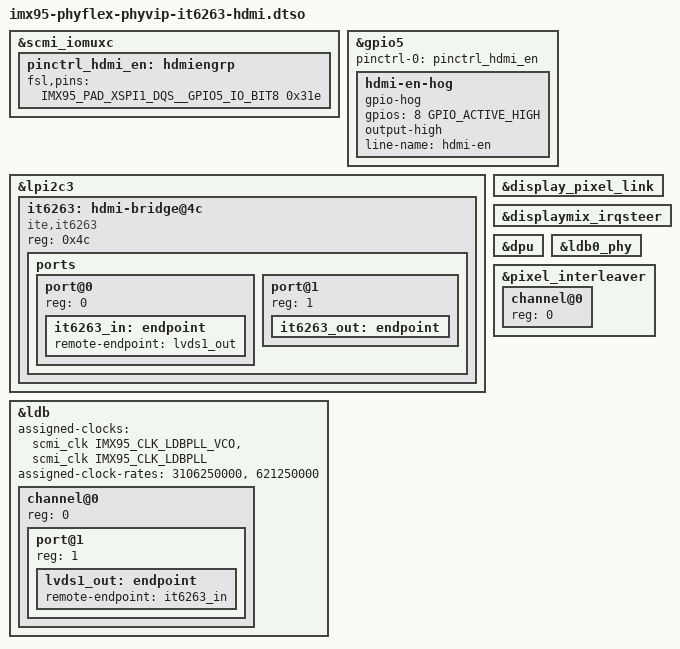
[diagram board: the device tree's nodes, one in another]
// SPDX-License-Identifier: GPL-2.0-only
/*
 * Device Tree Overlay: ITE IT6263 LVDS-to-HDMI bridge
 * Target board: imx95-phyflex-phyvip-1
 *
 * Aktivierung in /boot/overlays.txt:
 *   fit_overlay_conf=conf-imx95-phyflex-phyvip-it6263-hdmi.dtbo
 *
 * LDB-KANAL: channel@0, NICHT channel@1.
 *
 * Diese Datei stammt aus todo/meta-hdmi und war dort fuer das
 * phyBOARD-Libra RDK geschrieben, wo die Bruecke an LVDS2 = LDB channel@1
 * haengt. Auf dem phyVIP-Carrier ist die Belegung anders; die urspruenglich
 * uebernommene channel@1-Fassung hat deshalb einen Kanal bespielt, der hier
 * gar nicht angeschlossen ist. Aus dem Carrier-Schaltplan
 * PV-05832-001-1645-0-004:
 *
 *   Blatt 11 "FPSC_Unused"  -> FPSC LVDS2 (Netze X_LVDS1_*) endet in
 *                              No-Connects. LDB channel@1 ist tot.
 *   Blatt 9  "FPSC_Connector" -> FPSC LVDS1 (Netze X_LVDS0_*) fuehrt nach
 *                              13-C4/13-D4, also auf CON2.
 *   Blatt 13 "Erweiterungsboard-Steckverbinder" -> X_LVDS0_* liegt auf CON2
 *                              (X13X13). Dort sitzt die Bruecke.
 *
 * Messbar am Symptom: mit channel@1 blieb disp1pix auf 24 MHz mit
 * Enable-Count 0, obwohl der Modeset fehlerfrei durchlief, und der IT6263
 * meldete "failed to wait for video stable".
 *
 * PIXELTAKT: eingestellt auf 88,75 MHz = 1440x900@60.
 * Der NXP-Fork des Treibers (drivers/gpu/drm/bridge/it6263.c, bindet trotz
 * compatible "ite,it6263") fuehrt in it6263_bad_mode_db eine Sperrliste, in
 * der unter anderem 1600x900@60 und 1280x1024@60 stehen. Der native Modus
 * eines 1600x900-Monitors ist damit nicht erreichbar; 1440x900@60 ist der
 * hoechste Modus, den dieser Treiber durchlaesst.
 */
 
#include "imx95-pinfunc.h"
#include "imx95-clock.h"
#include <dt-bindings/gpio/gpio.h>
#include <dt-bindings/interrupt-controller/irq.h>

/dts-v1/;
/plugin/;

&scmi_iomuxc {
	pinctrl_hdmi_en: hdmiengrp {
		fsl,pins = <
			IMX95_PAD_XSPI1_DQS__GPIO5_IO_BIT8 0x31e
		>;
	};
};

/* GPIO5 Bit 8 dauerhaft high → HDMI_EN am HDMI2C4-5F2 → 5V + HPD aktiv */
&gpio5 {
	pinctrl-names = "default";
	pinctrl-0 = <&pinctrl_hdmi_en>;

	hdmi-en-hog {
		gpio-hog;
		gpios = <8 GPIO_ACTIVE_HIGH>;
		output-high;
		line-name = "hdmi-en";
	};
};

&lpi2c3 {

	#address-cells = <1>;
	#size-cells = <0>;
	status = "okay";

	it6263: hdmi-bridge@4c {
		compatible = "ite,it6263";
		reg = <0x4c>;
        status = "okay";

		ports {
			#address-cells = <1>;
			#size-cells = <0>;

			/* Input: LVDS von LDB channel@0 (FPSC-LVDS1, Netze X_LVDS0_*, ueber CON2) */
			port@0 {
				reg = <0>;
				it6263_in: endpoint {
					remote-endpoint = <&lvds1_out>;
				};
			};

			/* Output: HDMI sink */
			port@1 {
				reg = <1>;
				it6263_out: endpoint {
					/* Leave open — IT6263 drives HDMI directly */
				};
			};
		};
	};
};



/*
 * Display pipeline (same as imx95-phyflex-libra-rdk-lvds.dtsi):
 *   DPU → pixel_interleaver → display_pixel_link → LDB → IT6263 → HDMI
 */
&display_pixel_link {
	status = "okay";
};

&displaymix_irqsteer {
	status = "okay";
};

&dpu {
	status = "okay";
};

&ldb {
	#address-cells = <1>;
	#size-cells = <0>;
	/*
	 * LDBPLL fuer 1440x900@60: Pixeltakt = 88,75 MHz
	 * ldb_pll_div7 = LDBPLL / 7 -> 621,25 MHz / 7 = 88,75 MHz (exakt)
	 * LDBPLL_VCO   = 621,25 MHz * 5 = 3106,25 MHz, dasselbe ~3-GHz-Band wie
	 * die Hersteller-Referenz imx95-phyflex-libra-rdk-lvds.dtsi (3040,8 MHz).
	 *
	 * Vorher stand hier 148,5 MHz fuer 1920x1080@60. Das passte zu keinem
	 * Modus, den DRM an diesem Monitor anbietet, und der Kommentar
	 * "disp1pix nimmt ldb_pll_pixel automatisch" stimmt nicht: disp1pix blieb
	 * gemessen auf 24 MHz stehen.
	 */
	assigned-clocks = <&scmi_clk IMX95_CLK_LDBPLL_VCO>,
			  <&scmi_clk IMX95_CLK_LDBPLL>;
	assigned-clock-rates = <3106250000>, <621250000>;
	status = "okay";

	channel@0 {
		#address-cells = <1>;
		#size-cells = <0>;
		status = "okay";
		reg = <0>;

		port@1 {
			reg = <1>;
			lvds1_out: endpoint {
				remote-endpoint = <&it6263_in>;
			};
		};
	};
};

&ldb0_phy {
	status = "okay";
};

&pixel_interleaver {
	#address-cells = <1>;
	#size-cells = <0>;
	status = "okay";

	channel@0 {
		reg = <0>;
		status = "okay";
	};
};
